# wiz16b8m4ct3_0_WIZ16B8M4CT3 register map
Vendor: Texas Instruments
Registers are 32-bit, read-write, reset 0x0 unless marked. A register's access mark holds for its fields unless they carry their own. Offsets are as the file gives them; [hi:lo] are bit positions.

## wiz16b8m4ct3_0_WIZ16B8M4CT3 (part 5 of 12)
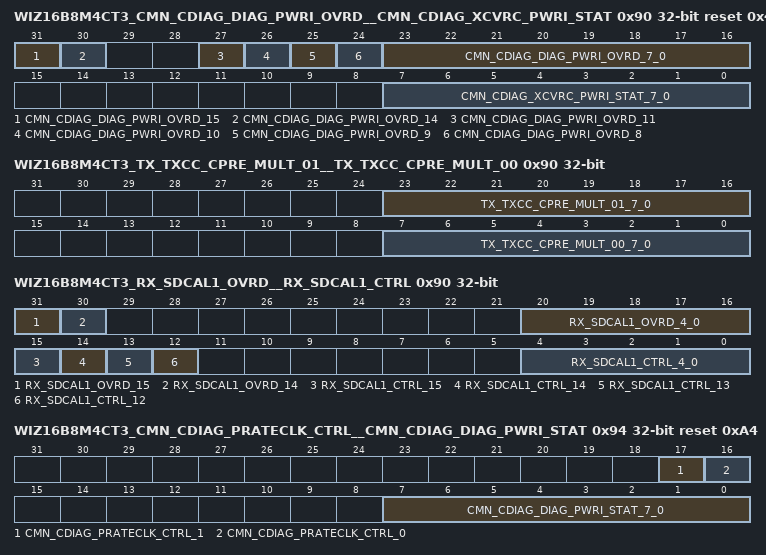
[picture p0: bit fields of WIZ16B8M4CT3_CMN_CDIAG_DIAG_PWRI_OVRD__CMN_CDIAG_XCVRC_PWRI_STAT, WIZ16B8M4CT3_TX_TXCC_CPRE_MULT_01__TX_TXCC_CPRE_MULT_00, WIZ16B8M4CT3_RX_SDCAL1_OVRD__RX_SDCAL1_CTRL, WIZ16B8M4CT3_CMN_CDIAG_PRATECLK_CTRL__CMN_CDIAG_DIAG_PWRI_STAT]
0x90 WIZ16B8M4CT3_CMN_CDIAG_DIAG_PWRI_OVRD__CMN_CDIAG_XCVRC_PWRI_STAT access per field reset 0x4240024
  [31] CMN_CDIAG_DIAG_PWRI_OVRD_15 rw — Power island controller input override enable: When enabled, the power island control state machine input override bits in this register will drive the power island control state machine directly, and override any control from other state machines in the macro. Note: The CDB power island must be triggered to be enabled, by accessing a register outside of the common control module control and diagnostic registers space, prior to enabling this function. Note: This bit must never change state in the same register write that any of the override bits it controls in this register are changed. 1'b0: Override disabled 1'b1: Override enabled
  [30] CMN_CDIAG_DIAG_PWRI_OVRD_14 rw — Power island controller output override enable: When enabled, the power island control state machine output override bits in this register will drive the power island control state machine outputs, and override any control from power island control state machine. Note: This bit must never change state in the same register write that any of the override bits it controls in this register are changed. 1'b0: Override disabled 1'b1: Override enabled
  [27] CMN_CDIAG_DIAG_PWRI_OVRD_11 rw — Power suspend request override: When enabled, this bit will override the power_suspend_req input of the power island control state machine.
  [26] CMN_CDIAG_DIAG_PWRI_OVRD_10 ro — Power suspend acknowledge: This is the current state of the power_suspend_ack output from the power island control state machine. Note: This bit will always be set to 1'b1 after the power island is enabled, as a function of the power island controller input override enable bit in this register.
  [25] CMN_CDIAG_DIAG_PWRI_OVRD_9 rw — Power recover request override: When enabled, this bit will override the power_recover_req input of the power island control state machine.
  [24] CMN_CDIAG_DIAG_PWRI_OVRD_8 ro — Power recover acknowledge: This is the current state of the power_recover_ack output from the power island control state machine. Note: This bit will always be set to 1'b1 after the power island is enabled, as a function of the power island controller input override enable bit in this register.
  [23:16] CMN_CDIAG_DIAG_PWRI_OVRD_7_0 rw — Power island controller output override: When enabled, the bits in this field will override the output signals from the power island control state machine. The following are the power island control state machine output signals, and the bits in this field that they are associated with. Bit 7: state_sandh Bit 6: state_ret_save Bit 5: state_ret_restore (active low) Bit 4: power_en_ph_1 Bit 3: power_en_ph_2 Bit 2: power_isolation Bit 1: power_por_reset_n Bit 0: power_rstr_reset_n The default value of the bits in this register are such that the power island is not forced to be switched on when the power island controller output override enable bit in this register is enabled. When using this register to switch this power island on and off, the bits in this field are required to change in a specific order with individual register writes. The writes must happen in the order specified below. 8'b00100100 : Power island is not being forced on 8'b10100100 8'b10110100 8'b10111100 8'b10111111 8'b10111011 8'b00111011 : Power island is being forced on 8'b10111011 8'b10111111 8'b11111111 8'b10111111 8'b10111110 8'b10100110 : Power island is being forced off, and in state retention 8'b10110110 8'b10111110 8'b10111111 8'b10011111 8'b10111111 8'b10111011 8'b00111011 : Power island is being forced on, with state restored
  [7:0] CMN_CDIAG_XCVRC_PWRI_STAT_7_0 ro — Power island controller output status: This field indicates the current state of the output signals from the power island control state machine. The following are the power island control state machine output signals, and the bits in this field that they are associated with. Bit 7: state_sandh Bit 6: state_ret_save Bit 5: state_ret_restore (active low) Bit 4: power_en_ph_1 Bit 3: power_en_ph_2 Bit 2: power_isolation Bit 1: power_por_reset_n Bit 0: power_rstr_reset_n
0x90 WIZ16B8M4CT3_TX_TXCC_CPRE_MULT_01__TX_TXCC_CPRE_MULT_00
  [23:16] TX_TXCC_CPRE_MULT_01_7_0 — Calculated pre emphasis multiplier value 01: The value in this field specifies the multiplier value used to generate the calculated pre emphasis value from the FS value when tx_deemphasis[1:0] = 2'b01. The following describes the multiplier value each bit in this field corresponds to. Bit 7 : 128/128 = 1.000000 Bit 6 : 64/128 = 0.500000 Bit 5 : 32/128 = 0.250000 Bit 4 : 16/128 = 0.125000 Bit 3 : 8/128 = 0.062500 Bit 2 : 4/128 = 0.031250 Bit 1 : 2/128 = 0.015625 Bit 0 : 1/128 = 0.0078125 Note: The output of the multiplier is 6 bits wide. It is possible to set the multiplier value here to a sufficiently large value to cause the multiplier result to be such that it can't be represented by a 6 bit value. In such a case, the multiplier output will be driven to 6'b111111.
  [7:0] TX_TXCC_CPRE_MULT_00_7_0 — Calculated pre emphasis multiplier value 00: The value in this field specifies the multiplier value used to generate the calculated pre emphasis value from the FS value when tx_deemphasis[1:0] = 2'b00. The following describes the multiplier value each bit in this field corresponds to. Bit 7 : 128/128 = 1.000000 Bit 6 : 64/128 = 0.500000 Bit 5 : 32/128 = 0.250000 Bit 4 : 16/128 = 0.125000 Bit 3 : 8/128 = 0.062500 Bit 2 : 4/128 = 0.031250 Bit 1 : 2/128 = 0.015625 Bit 0 : 1/128 = 0.0078125 Note: The output of the multiplier is 6 bits wide. It is possible to set the multiplier value here to a sufficiently large value to cause the multiplier result to be such that it can't be represented by a 6 bit value. In such a case, the multiplier output will be driven to 6'b111111.
0x90 WIZ16B8M4CT3_RX_SDCAL1_OVRD__RX_SDCAL1_CTRL access per field
  [31] RX_SDCAL1_OVRD_15 rw — Calibration code override enable: Activation (1'b1) of this register bit allows the calibration code determined during the automatic calibration process to be overridden. The override value is specified using the calibration code override value field of this register.
  [30] RX_SDCAL1_OVRD_14 rw — Analog calibration enable override: Activation (1'b1) of this register bit will force the analog calibration circuits to be enabled by activating the rxda_sd_cal_1_en enable and the rxda_sd_cal_1_clk clock.
  [20:16] RX_SDCAL1_OVRD_4_0 rw — Calibration code override value: These bits are used to override the calibration code determined during the automatic calibration process. The code written to these bits is valid when the calibration code override enable bit in this register is active. The codes in this field correspond to those described in the calibration code field in the Signal detect calibration 1 control register (!) on page 235.
  [15] RX_SDCAL1_CTRL_15 rw — Start calibration: Activating (1'b1) this bit will start the calibration process. This signal must remain active until the calibration process is complete. To start another calibration process, this register must first be set inactive (1'b0) until the bandbap calibration process done bit in this register is cleared. Note: This bit is intended to be for diagnostics purposes only. This calibration process is automatically activated internally by the power state machine. When using this bit, the user must wait until after the internally activated process completes.
  [14] RX_SDCAL1_CTRL_14 ro — Calibration process done: This bit will be set to 1'b1 when the calibration process is complete. It will be cleared by cmn_reset_n, or by the deactivation of the start calibration bit in this register after calibration is complete. Note: This bit is intended to be for diagnostics purposes only. Note: This bit is not likely to be observed as being set after internal automatic calibration is complete, because the internally generated run signal will be driven inactive immediately after the done signal is activated, and therefore the internal done signal will be cleared. Note: Three cmn_ref_clk cycles are required after the start of the calibration process to clear this signal.
  [13] RX_SDCAL1_CTRL_13 ro — No analog calibration response : This signal indicates that the calibration function has gone through the entire calibration process, reached the final calibration value, and the analog has not responded indicating that a valid calibration value has been reached. Note: Due to the nature of the calibration process, it is not possible to determine if the analog responded or not for the lowest code of 4'b1001. The reason for this is, when sequencing to lower codes, the calibration function is looking for the analog response to transition from 1'b1 to 1'b0. If the lowest calibration code is the correct code, the analog will respond with 1'b1, and the algorithm can't sequence to a lower code to look for the transition from 1'b1 to 1'b0. Similarly, if the analog is not responding, it is not possible to sequence to a lower code to detect this. Therefore, even when the calibration function selects this calibration code as valid, this bit will be set.
  [12] RX_SDCAL1_CTRL_12 ro — Current analog comparator response: This is the current state of the analog comparator response signal (rxda_sd_cal_0_comp). This signal is not synchronized, and is provided for diagnostic purposes only.
  [4:0] RX_SDCAL1_CTRL_4_0 ro — Calibration code: This is the calibration code that was determined by the calibration process. The following indicates how this encoding maps to the rxda_sd_cal_1_up and rxda_sd_cal_1_code signals going to the analog calibration function. The five bit value on the left is the value of this field. The one bit value on the right corresponds to the value of rxda_sd_cal_1_up. The four bit field corresponds to the value of rxda_sd_cal_1_code. 5'b01111 : 1'b1, 4'b1111 5'b01110 : 1'b1, 4'b1110 ... 5'b00010 : 1'b1, 4'b0010 5'b00001 : 1'b1, 4'b0001 5'b00000 : 1'b1, 4'b0000 5'b11111 : 1'b0, 4'b0001 5'b11110 : 1'b0, 4'b0010 ... 5'b10010 : 1'b0, 4'b1110 5'b10001 : 1'b0, 4'b1111
0x94 WIZ16B8M4CT3_CMN_CDIAG_PRATECLK_CTRL__CMN_CDIAG_DIAG_PWRI_STAT access per field reset 0xA4
  [17] CMN_CDIAG_PRATECLK_CTRL_1 rw — Common PLL 1 full rate and data rate source clock select: Selects the PLL source clock to use when generating the cmn_pll1_clk_fullrt, cmn_pll1_clk_datart0, and cmn_pll1_clk_datart1 clocks. 1'b0 : cmnda_pll1_clk_0 1'b1 : cmnda_pll1_clk_1
  [16] CMN_CDIAG_PRATECLK_CTRL_0 rw — Common PLL 0 full rate and data rate source clock select: Selects the PLL source clock to use when generating the cmn_pll0_clk_fullrt, cmn_pll0_clk_datart0, and cmn_pll0_clk_datart1 clocks. 1'b0 : cmnda_pll0_clk_0 1'b1 : cmnda_pll0_clk_1
  [7:0] CMN_CDIAG_DIAG_PWRI_STAT_7_0 ro — Power island controller output status: This field indicates the current state of the output signals from the power island control state machine. The following are the power island control state machine output signals, and the bits in this field that they are associated with. Bit 7: state_sandh Bit 6: state_ret_save Bit 5: state_ret_restore (active low) Bit 4: power_en_ph_1 Bit 3: power_en_ph_2 Bit 2: power_isolation Bit 1: power_por_reset_n Bit 0: power_rstr_reset_n
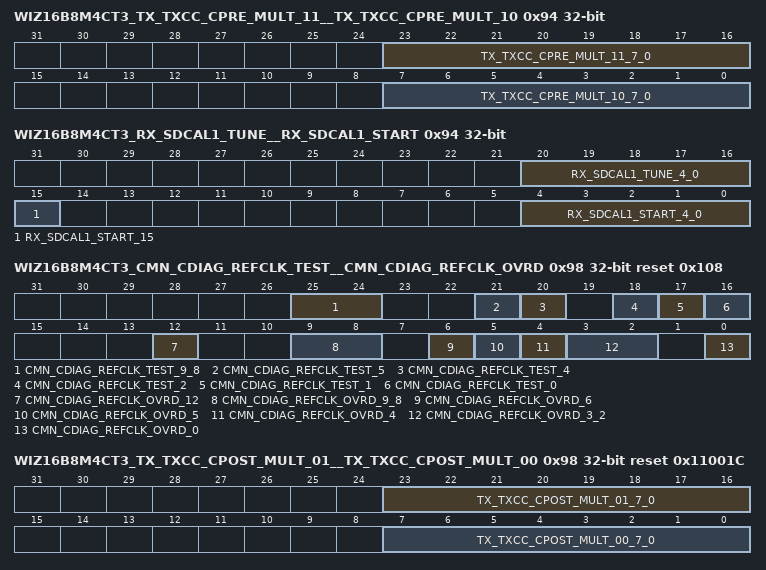
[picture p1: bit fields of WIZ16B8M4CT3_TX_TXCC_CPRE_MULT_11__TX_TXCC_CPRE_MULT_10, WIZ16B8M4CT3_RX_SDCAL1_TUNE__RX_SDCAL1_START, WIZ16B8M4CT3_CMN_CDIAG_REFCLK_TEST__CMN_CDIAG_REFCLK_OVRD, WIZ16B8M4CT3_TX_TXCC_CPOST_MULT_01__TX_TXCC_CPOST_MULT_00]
0x94 WIZ16B8M4CT3_TX_TXCC_CPRE_MULT_11__TX_TXCC_CPRE_MULT_10
  [23:16] TX_TXCC_CPRE_MULT_11_7_0 — Calculated pre emphasis multiplier value 11: The value in this field specifies the multiplier value used to generate the calculated pre emphasis value from the FS value when tx_deemphasis[1:0] = 2'b11. The following describes the multiplier value each bit in this field corresponds to. Bit 7 : 128/128 = 1.000000 Bit 6 : 64/128 = 0.500000 Bit 5 : 32/128 = 0.250000 Bit 4 : 16/128 = 0.125000 Bit 3 : 8/128 = 0.062500 Bit 2 : 4/128 = 0.031250 Bit 1 : 2/128 = 0.015625 Bit 0 : 1/128 = 0.0078125 Note: The output of the multiplier is 6 bits wide. It is possible to set the multiplier value here to a sufficiently large value to cause the multiplier result to be such that it can't be represented by a 6 bit value. In such a case, the multiplier output will be driven to 6'b111111.
  [7:0] TX_TXCC_CPRE_MULT_10_7_0 — Calculated pre emphasis multiplier value 10: The value in this field specifies the multiplier value used to generate the calculated pre emphasis value from the FS value when tx_deemphasis[1:0] = 2'b10. The following describes the multiplier value each bit in this field corresponds to. Bit 7 : 128/128 = 1.000000 Bit 6 : 64/128 = 0.500000 Bit 5 : 32/128 = 0.250000 Bit 4 : 16/128 = 0.125000 Bit 3 : 8/128 = 0.062500 Bit 2 : 4/128 = 0.031250 Bit 1 : 2/128 = 0.015625 Bit 0 : 1/128 = 0.0078125 Note: The output of the multiplier is 6 bits wide. It is possible to set the multiplier value here to a sufficiently large value to cause the multiplier result to be such that it can't be represented by a 6 bit value. In such a case, the multiplier output will be driven to 6'b111111.
0x94 WIZ16B8M4CT3_RX_SDCAL1_TUNE__RX_SDCAL1_START
  [20:16] RX_SDCAL1_TUNE_4_0 — Calibration tune value: The value of this field is added to the automatically calibrated code, or the override code if override is enabled. Note: This value is a twos complement value, so the calibrated code can be increased or decreased.
  [15] RX_SDCAL1_START_15 — Calibration direction: This controls the direction that the automatic calibration process steps the calibration codes in. 1'b0 : From 5'b10001 to 5'b01111. 1'b1 : From 5'b01111 to 5'b00000.
  [4:0] RX_SDCAL1_START_4_0 — Start calibration code: This is the calibration code that the calibration process starts with when automatic calibration is run. The codes in this field correspond to those described in the calibration code field in the Signal detect calibration 1 control register (!) on page 235.
0x98 WIZ16B8M4CT3_CMN_CDIAG_REFCLK_TEST__CMN_CDIAG_REFCLK_OVRD access per field reset 0x108
  [25:24] CMN_CDIAG_REFCLK_TEST_9_8 rw — Reserved - spare
  [21] CMN_CDIAG_REFCLK_TEST_5 rw — Reference clock driver 0 test mode enable: Enables the reference clock driver DC test mode, by controlling the cmnda_ref_clk0_drv_test_en signal going into the analog.
  [20] CMN_CDIAG_REFCLK_TEST_4 rw — Reference clock driver 0 test mode value: When enabled by the reference clock driver 0 test mode enable bit in this register, the value in this bit will be driven by the reference clock driver, by controlling the cmnda_ref_clk0_drv_test_val signal going into the analog.
  [18] CMN_CDIAG_REFCLK_TEST_2 rw — Reference clock receiver test mode enable: Enables the reference clock receiver DC test mode, by controlling the cmnda_ref_clk_rcv_test_en signal going into the analog.
  [17] CMN_CDIAG_REFCLK_TEST_1 ro — Reference clock receiver test mode PLL value: When enabled by the reference clock receiver test mode enable bit in this register, the value in this bit will be the value present on the PLL reference clock receiver. This bit is driven by thecmnda_ref_clk_rcv_test_pll_val signal driven from the analog.
  [16] CMN_CDIAG_REFCLK_TEST_0 ro — Reference clock receiver test mode digital value: When enabled by the reference clock receiver test mode enable bit in this register, the value in this bit will be the value present on the digital reference clock receiver. This bit is driven by thecmnda_ref_clk_rcv_test_dig_val signal driven from the analog.
  [12] CMN_CDIAG_REFCLK_OVRD_12 rw — Derived reference clock source select: Selects which PLL is the source for the derived reference clock, by driving the cmnda_ref_clk_der_src_sel signal to the analog. 1'b0: PLL 0 1'b1: PLL 1
  [9:8] CMN_CDIAG_REFCLK_OVRD_9_8 rw — Digital reference clock receiver hysteresis adjust: Control the amount of hysteresis used for the digital reference clock receiver, by driving the cmnda_ref_clk_dig_hyst_adj signal to the analog. 2'b00: -1X nominal 2'b01: Nominal 2'b10: +1X nominal 2'b11: +2X nominal
  [6] CMN_CDIAG_REFCLK_OVRD_6 rw — Analog reference clock enable override: This bit can be used to force the cmnda_ref_clk_en signal going to the analog to the active state. 1'b0 : No effect on the state of the cmnda_ref_clk_en signal. 1'b1 : The cmnda_ref_clk_en is forced to the active state.
  [5] CMN_CDIAG_REFCLK_OVRD_5 rw — Reference clock AC coupling cap bypass: Controls the bypassing of the AC coupling caps in the differential receiver. 1'b0: AC coupling caps not bypassed. 1'b1: AC coupling caps bypassed.
  [4] CMN_CDIAG_REFCLK_OVRD_4 rw — Derived reference clock enable: Enables the derived reference clock function, by driving the cmnda_ref_clk_der_en signal to the analog. Note: The option of using this clock is only intended to be for PCIe modes of operation. 1'b0: Derived clock function disabled. 1'b1: Derived clock function enabled.
  [3:2] CMN_CDIAG_REFCLK_OVRD_3_2 rw — Reference clock high pass filter control: Controls the cutoff frequency of the high pass filter in the reference clock receiver input. This controls this function by controlling the cmnda_ref_clk_filt_ctrl signal going into the analog. The following are the valid settings for this field and the corresponding cut off frequencies. 2'b00 : 20 - 49 MHz 2'b01 : 50 - 99 MHz 2'b10 : 100 - 149 MHz 2'b11 : 150 - 166 MHz
  [0] CMN_CDIAG_REFCLK_OVRD_0 rw — Reference clock receiver circuit clock control: 1'b0 : The analog reference clock receiver circuit for the digital drives the cmn_ref_clk_rcv pin. 1'b1 : The analog reference clock receiver circuit for the PLL drives the cmn_ref_clk_rcv pin.
0x98 WIZ16B8M4CT3_TX_TXCC_CPOST_MULT_01__TX_TXCC_CPOST_MULT_00 reset 0x11001C
  [23:16] TX_TXCC_CPOST_MULT_01_7_0 — Calculated post emphasis multiplier value 01: The value in this field specifies the multiplier value used to generate the calculated post emphasis value from the FS value when tx_deemphasis[1:0] = 2'b01. The following describes the multiplier value each bit in this field corresponds to. Bit 7 : 128/128 = 1.000000 Bit 6 : 64/128 = 0.500000 Bit 5 : 32/128 = 0.250000 Bit 4 : 16/128 = 0.125000 Bit 3 : 8/128 = 0.062500 Bit 2 : 4/128 = 0.031250 Bit 1 : 2/128 = 0.015625 Bit 0 : 1/128 = 0.0078125 Note: The output of the multiplier is 6 bits wide. It is possible to set the multiplier value here to a sufficiently large value to cause the multiplier result to be such that it can't be represented by a 6 bit value. In such a case, the multiplier output will be driven to 6'b111111.
  [7:0] TX_TXCC_CPOST_MULT_00_7_0 — Calculated post emphasis multiplier value 00: The value in this field specifies the multiplier value used to generate the calculated post emphasis value from the FS value when tx_deemphasis[1:0] = 2'b00. The following describes the multiplier value each bit in this field corresponds to. Bit 7 : 128/128 = 1.000000 Bit 6 : 64/128 = 0.500000 Bit 5 : 32/128 = 0.250000 Bit 4 : 16/128 = 0.125000 Bit 3 : 8/128 = 0.062500 Bit 2 : 4/128 = 0.031250 Bit 1 : 2/128 = 0.015625 Bit 0 : 1/128 = 0.0078125 Note: The output of the multiplier is 6 bits wide. It is possible to set the multiplier value here to a sufficiently large value to cause the multiplier result to be such that it can't be represented by a 6 bit value. In such a case, the multiplier output will be driven to 6'b111111.
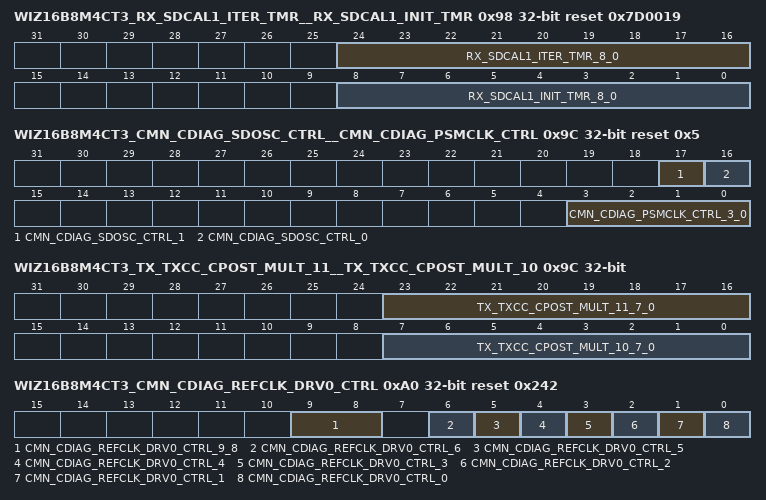
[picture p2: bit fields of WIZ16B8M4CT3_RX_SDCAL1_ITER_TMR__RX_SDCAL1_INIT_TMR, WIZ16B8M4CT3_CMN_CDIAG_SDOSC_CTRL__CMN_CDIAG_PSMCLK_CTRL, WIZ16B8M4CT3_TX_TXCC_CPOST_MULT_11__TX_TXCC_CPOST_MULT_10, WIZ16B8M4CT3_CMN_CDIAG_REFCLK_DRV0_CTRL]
0x98 WIZ16B8M4CT3_RX_SDCAL1_ITER_TMR__RX_SDCAL1_INIT_TMR reset 0x7D0019
  [24:16] RX_SDCAL1_ITER_TMR_8_0 — Iteration wait timer value: This is the number of cmn_ref_clk clocks to wait between when a value is placed on the calibration code signals going to the analog, and when the comparator value coming from the analog circuits can be checked. Note: This results in the minimum number of cmn_ref_clk clocks required to wait 5 uSec. Note: This should never be set to a value of less than 3.
  [8:0] RX_SDCAL1_INIT_TMR_8_0 — Initialization wait timer value: This is the number of cmn_ref_clk clocks to wait between when the analog calibration circuits are enabled, and when the first values are placed on the calibration code signals going to the analog. Note: This results in the minimum number of cmn_ref_clk clocks required to wait 1 uSec. Note: This should never be set to a value of less than 1.
0x9C WIZ16B8M4CT3_CMN_CDIAG_SDOSC_CTRL__CMN_CDIAG_PSMCLK_CTRL reset 0x5
  [17] CMN_CDIAG_SDOSC_CTRL_1 — Oscillator Enable Override Enable: This bit enables the oscillator enable override bit in this register to directly control the signal detect oscillator. 1'b0 : Override disabled. 1'b1 : Override enabled
  [16] CMN_CDIAG_SDOSC_CTRL_0 — Oscillator Enable Override: When enabled by the oscillator enable override enable bit in this register, this bit can be used to directly control the enable of the signal detect oscillator. 1'b0 : Disabled. 1'b1 : Enabled
  [3:0] CMN_CDIAG_PSMCLK_CTRL_3_0 — PSM clock divider value: The value of this field is used to control the divider setting of the PSM clock divider. The following are the encoded value for this field. 4'b0000 : Reserved 4'b0001 : Divide by 1 4'b0010 : Divide by 2 4'b0011 : Divide by 3 ... 4'b1111 : Divide by 15
0x9C WIZ16B8M4CT3_TX_TXCC_CPOST_MULT_11__TX_TXCC_CPOST_MULT_10
  [23:16] TX_TXCC_CPOST_MULT_11_7_0 — Calculated post emphasis multiplier value 11: The value in this field specifies the multiplier value used to generate the calculated post emphasis value from the FS value when tx_deemphasis[1:0] = 2'b11. The following describes the multiplier value each bit in this field corresponds to. Bit 7 : 128/128 = 1.000000 Bit 6 : 64/128 = 0.500000 Bit 5 : 32/128 = 0.250000 Bit 4 : 16/128 = 0.125000 Bit 3 : 8/128 = 0.062500 Bit 2 : 4/128 = 0.031250 Bit 1 : 2/128 = 0.015625 Bit 0 : 1/128 = 0.0078125 Note: The output of the multiplier is 6 bits wide. It is possible to set the multiplier value here to a sufficiently large value to cause the multiplier result to be such that it can't be represented by a 6 bit value. In such a case, the multiplier output will be driven to 6'b111111.
  [7:0] TX_TXCC_CPOST_MULT_10_7_0 — Calculated post emphasis multiplier value 10: The value in this field specifies the multiplier value used to generate the calculated post emphasis value from the FS value when tx_deemphasis[1:0] = 2'b10. The following describes the multiplier value each bit in this field corresponds to. Bit 7 : 128/128 = 1.000000 Bit 6 : 64/128 = 0.500000 Bit 5 : 32/128 = 0.250000 Bit 4 : 16/128 = 0.125000 Bit 3 : 8/128 = 0.062500 Bit 2 : 4/128 = 0.031250 Bit 1 : 2/128 = 0.015625 Bit 0 : 1/128 = 0.0078125 Note: The output of the multiplier is 6 bits wide. It is possible to set the multiplier value here to a sufficiently large value to cause the multiplier result to be such that it can't be represented by a 6 bit value. In such a case, the multiplier output will be driven to 6'b111111.
0xA0 WIZ16B8M4CT3_CMN_CDIAG_REFCLK_DRV0_CTRL reset 0x242
  [9:8] CMN_CDIAG_REFCLK_DRV0_CTRL_9_8 — Clock driver drive current tune: Controls the amplitude of the reference clock driver, by controlling the cmnda_ref_clk0_itune signal going to the analog. The following is the encoding of this field. 2'b00: 300mV pk-pk differential 2'b01: 350mV pk-pk differential 2'b10: 400mV pk-pk differential 2'b11: 450mV pk-pk differential
  [6] CMN_CDIAG_REFCLK_DRV0_CTRL_6 — Reference clock driver high Z: When the reference clock driver is disabled, this controls if the driver outputs are high Z or pulled low, by controlling the cmnda_ref_clk0_drv_highz signal going to the analog. 1'b0: Driver outputs pulled low 1'b1: Driver outputs high Z
  [5] CMN_CDIAG_REFCLK_DRV0_CTRL_5 — Clock driver termination: Enables the termination in the reference clock driver, by controlling the cmnda_ref_clk0_termination signal going to the analog. 1'b0: Disabled 1'b1: Enabled
  [4] CMN_CDIAG_REFCLK_DRV0_CTRL_4 — Clock select: Selects which reference clock that will be driven by the reference clock driver, by controlling the cmnda_ref_clk0_clk_select signal going to the analog. 1'b0: Received reference clock 1'b1: Derived reference clock
  [3] CMN_CDIAG_REFCLK_DRV0_CTRL_3 — Clock gate enable override enable: This bit enables the clock gate enable override bit in this register to override the clock gate of the reference clock driver.
  [2] CMN_CDIAG_REFCLK_DRV0_CTRL_2 — Clock gate enable override: When enabled by the clock gate enable override enable bit in this register, this bit can be used to directly control the clock gate enable of the reference clock driver by controlling the cmnda_ref_clk0_clk_gate_en signal going to the analog.
  [1] CMN_CDIAG_REFCLK_DRV0_CTRL_1 — Driver enable override enable: This bit enables the driver enable override bit in this register to override the enable of the reference clock driver. Note: This driver must not be enabled when a reference clock signal is being driven to the reference clock 0 bumps.
  [0] CMN_CDIAG_REFCLK_DRV0_CTRL_0 — Driver enable override: When enabled by the driver enable override enable bit in this register, this bit can be used to directly control the enable of the reference clock driver by controlling the cmnda_ref_clk0_drv_en signal going to the analog. Note: This driver must not be enabled when a reference clock signal is being driven to the reference clock 0 bumps.
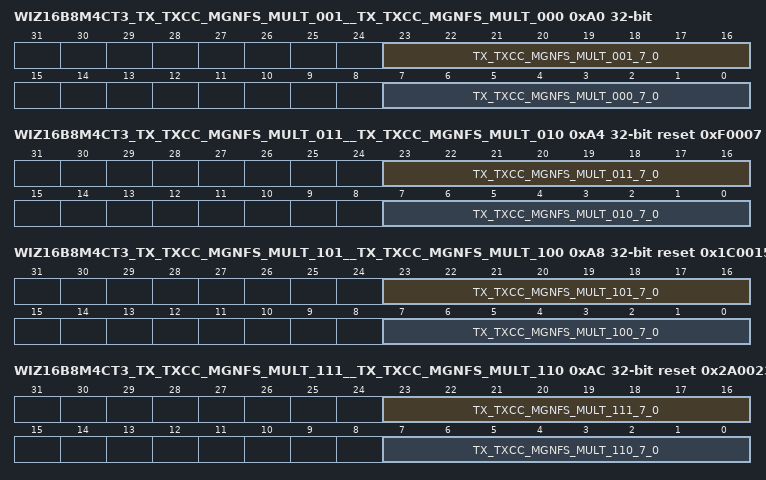
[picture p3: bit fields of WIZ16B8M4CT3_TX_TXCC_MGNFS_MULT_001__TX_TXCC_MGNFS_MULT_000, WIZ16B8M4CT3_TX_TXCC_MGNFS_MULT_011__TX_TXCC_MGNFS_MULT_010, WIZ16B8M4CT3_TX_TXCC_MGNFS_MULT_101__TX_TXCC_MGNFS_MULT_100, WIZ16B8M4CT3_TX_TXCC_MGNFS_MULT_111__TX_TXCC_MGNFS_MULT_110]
0xA0 WIZ16B8M4CT3_TX_TXCC_MGNFS_MULT_001__TX_TXCC_MGNFS_MULT_000
  [23:16] TX_TXCC_MGNFS_MULT_001_7_0 — Margin full swing multiplier value 001: The value in this field specifies the multiplier value used to generate the margin value from the resistor calibration value when tx_vmargin = 3'b001 and tx_low_power_swing_en = 1'b0. The following describes the multiplier value each bit in this field corresponds to. Bit 7 : 128/128 = 1.000000 Bit 6 : 64/128 = 0.500000 Bit 5 : 32/128 = 0.250000 Bit 4 : 16/128 = 0.125000 Bit 3 : 8/128 = 0.062500 Bit 2 : 4/128 = 0.031250 Bit 1 : 2/128 = 0.015625 Bit 0 : 1/128 = 0.0078125 Note: The largest value this is allowed to be set to is 54/128. Note: The output of the multiplier is 6 bits wide. It is possible to set the multiplier value here to a sufficiently large value to cause the multiplier result to be such that it can't be represented by a 6 bit value. In such a case, the multiplier output will be driven to 6'b111111.
  [7:0] TX_TXCC_MGNFS_MULT_000_7_0 — Margin full swing multiplier value 000: The value in this field specifies the multiplier value used to generate the margin value from the resistor calibration value when tx_vmargin = 3'b000 and tx_low_power_swing_en = 1'b0. The following describes the multiplier value each bit in this field corresponds to. Bit 7 : 128/128 = 1.000000 Bit 6 : 64/128 = 0.500000 Bit 5 : 32/128 = 0.250000 Bit 4 : 16/128 = 0.125000 Bit 3 : 8/128 = 0.062500 Bit 2 : 4/128 = 0.031250 Bit 1 : 2/128 = 0.015625 Bit 0 : 1/128 = 0.0078125 Note: The largest value this is allowed to be set to is 54/128. Note: The output of the multiplier is 6 bits wide. It is possible to set the multiplier value here to a sufficiently large value to cause the multiplier result to be such that it can't be represented by a 6 bit value. In such a case, the multiplier output will be driven to 6'b111111.
0xA4 WIZ16B8M4CT3_TX_TXCC_MGNFS_MULT_011__TX_TXCC_MGNFS_MULT_010 reset 0xF0007
  [23:16] TX_TXCC_MGNFS_MULT_011_7_0 — Margin full swing multiplier value 011: The value in this field specifies the multiplier value used to generate the margin value from the resistor calibration value when tx_vmargin = 3'b011 and tx_low_power_swing_en = 1'b0. The following describes the multiplier value each bit in this field corresponds to. Bit 7 : 128/128 = 1.000000 Bit 6 : 64/128 = 0.500000 Bit 5 : 32/128 = 0.250000 Bit 4 : 16/128 = 0.125000 Bit 3 : 8/128 = 0.062500 Bit 2 : 4/128 = 0.031250 Bit 1 : 2/128 = 0.015625 Bit 0 : 1/128 = 0.0078125 Note: The largest value this is allowed to be set to is 54/128. Note: The output of the multiplier is 6 bits wide. It is possible to set the multiplier value here to a sufficiently large value to cause the multiplier result to be such that it can't be represented by a 6 bit value. In such a case, the multiplier output will be driven to 6'b111111.
  [7:0] TX_TXCC_MGNFS_MULT_010_7_0 — Margin full swing multiplier value 010: The value in this field specifies the multiplier value used to generate the margin value from the resistor calibration value when tx_vmargin = 3'b010 and tx_low_power_swing_en = 1'b0. The following describes the multiplier value each bit in this field corresponds to. Bit 7 : 128/128 = 1.000000 Bit 6 : 64/128 = 0.500000 Bit 5 : 32/128 = 0.250000 Bit 4 : 16/128 = 0.125000 Bit 3 : 8/128 = 0.062500 Bit 2 : 4/128 = 0.031250 Bit 1 : 2/128 = 0.015625 Bit 0 : 1/128 = 0.0078125 Note: The largest value this is allowed to be set to is 54/128. Note: The output of the multiplier is 6 bits wide. It is possible to set the multiplier value here to a sufficiently large value to cause the multiplier result to be such that it can't be represented by a 6 bit value. In such a case, the multiplier output will be driven to 6'b111111.
0xA8 WIZ16B8M4CT3_TX_TXCC_MGNFS_MULT_101__TX_TXCC_MGNFS_MULT_100 reset 0x1C0015
  [23:16] TX_TXCC_MGNFS_MULT_101_7_0 — Margin full swing multiplier value 101: The value in this field specifies the multiplier value used to generate the margin value from the resistor calibration value when tx_vmargin = 3'b101 and tx_low_power_swing_en = 1'b0. The following describes the multiplier value each bit in this field corresponds to. Bit 7 : 128/128 = 1.000000 Bit 6 : 64/128 = 0.500000 Bit 5 : 32/128 = 0.250000 Bit 4 : 16/128 = 0.125000 Bit 3 : 8/128 = 0.062500 Bit 2 : 4/128 = 0.031250 Bit 1 : 2/128 = 0.015625 Bit 0 : 1/128 = 0.0078125 Note: The largest value this is allowed to be set to is 54/128. Note: The output of the multiplier is 6 bits wide. It is possible to set the multiplier value here to a sufficiently large value to cause the multiplier result to be such that it can't be represented by a 6 bit value. In such a case, the multiplier output will be driven to 6'b111111.
  [7:0] TX_TXCC_MGNFS_MULT_100_7_0 — Margin full swing multiplier value 100: The value in this field specifies the multiplier value used to generate the margin value from the resistor calibration value when tx_vmargin = 3'b100 and tx_low_power_swing_en = 1'b0. The following describes the multiplier value each bit in this field corresponds to. Bit 7 : 128/128 = 1.000000 Bit 6 : 64/128 = 0.500000 Bit 5 : 32/128 = 0.250000 Bit 4 : 16/128 = 0.125000 Bit 3 : 8/128 = 0.062500 Bit 2 : 4/128 = 0.031250 Bit 1 : 2/128 = 0.015625 Bit 0 : 1/128 = 0.0078125 Note: The largest value this is allowed to be set to is 54/128. Note: The output of the multiplier is 6 bits wide. It is possible to set the multiplier value here to a sufficiently large value to cause the multiplier result to be such that it can't be represented by a 6 bit value. In such a case, the multiplier output will be driven to 6'b111111.
0xAC WIZ16B8M4CT3_TX_TXCC_MGNFS_MULT_111__TX_TXCC_MGNFS_MULT_110 reset 0x2A0023
  [23:16] TX_TXCC_MGNFS_MULT_111_7_0 — Margin full swing multiplier value 111: The value in this field specifies the multiplier value used to generate the margin value from the resistor calibration value when tx_vmargin = 3'b111 and tx_low_power_swing_en = 1'b0. The following describes the multiplier value each bit in this field corresponds to. Bit 7 : 128/128 = 1.000000 Bit 6 : 64/128 = 0.500000 Bit 5 : 32/128 = 0.250000 Bit 4 : 16/128 = 0.125000 Bit 3 : 8/128 = 0.062500 Bit 2 : 4/128 = 0.031250 Bit 1 : 2/128 = 0.015625 Bit 0 : 1/128 = 0.0078125 Note: The largest value this is allowed to be set to is 54/128. Note: The output of the multiplier is 6 bits wide. It is possible to set the multiplier value here to a sufficiently large value to cause the multiplier result to be such that it can't be represented by a 6 bit value. In such a case, the multiplier output will be driven to 6'b111111.
  [7:0] TX_TXCC_MGNFS_MULT_110_7_0 — Margin full swing multiplier value 110: The value in this field specifies the multiplier value used to generate the margin value from the resistor calibration value when tx_vmargin = 3'b110 and tx_low_power_swing_en = 1'b0. The following describes the multiplier value each bit in this field corresponds to. Bit 7 : 128/128 = 1.000000 Bit 6 : 64/128 = 0.500000 Bit 5 : 32/128 = 0.250000 Bit 4 : 16/128 = 0.125000 Bit 3 : 8/128 = 0.062500 Bit 2 : 4/128 = 0.031250 Bit 1 : 2/128 = 0.015625 Bit 0 : 1/128 = 0.0078125 Note: The largest value this is allowed to be set to is 54/128. Note: The output of the multiplier is 6 bits wide. It is possible to set the multiplier value here to a sufficiently large value to cause the multiplier result to be such that it can't be represented by a 6 bit value. In such a case, the multiplier output will be driven to 6'b111111.
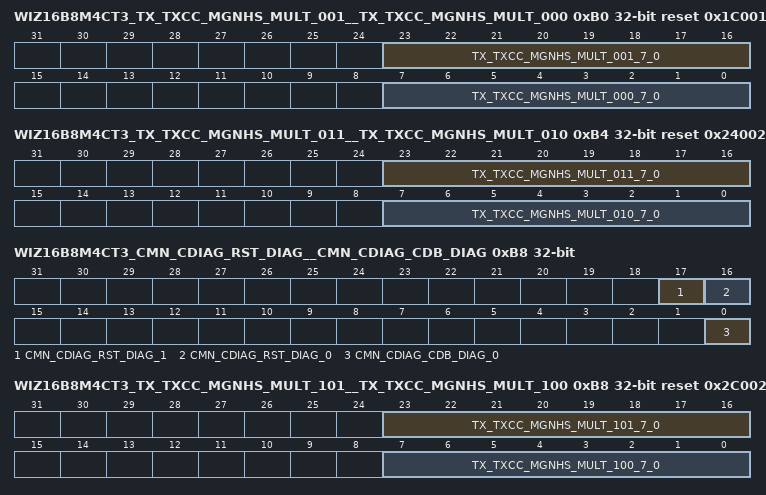
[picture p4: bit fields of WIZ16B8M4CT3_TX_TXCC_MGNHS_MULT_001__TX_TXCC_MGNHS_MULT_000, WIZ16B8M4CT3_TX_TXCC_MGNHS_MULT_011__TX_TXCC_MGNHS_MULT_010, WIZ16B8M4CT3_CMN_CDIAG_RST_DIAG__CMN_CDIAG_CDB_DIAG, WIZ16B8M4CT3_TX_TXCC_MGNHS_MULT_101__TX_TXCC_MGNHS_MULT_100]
0xB0 WIZ16B8M4CT3_TX_TXCC_MGNHS_MULT_001__TX_TXCC_MGNHS_MULT_000 reset 0x1C001C
  [23:16] TX_TXCC_MGNHS_MULT_001_7_0 — Margin half swing multiplier value 001: The value in this field specifies the multiplier value used to generate the margin value from the resistor calibration value when tx_vmargin = 3'b001 and tx_low_power_swing_en = 1'b1. The following describes the multiplier value each bit in this field corresponds to. Bit 7 : 128/128 = 1.000000 Bit 6 : 64/128 = 0.500000 Bit 5 : 32/128 = 0.250000 Bit 4 : 16/128 = 0.125000 Bit 3 : 8/128 = 0.062500 Bit 2 : 4/128 = 0.031250 Bit 1 : 2/128 = 0.015625 Bit 0 : 1/128 = 0.0078125 Note: The largest value this is allowed to be set to is 54/128. Note: The output of the multiplier is 6 bits wide. It is possible to set the multiplier value here to a sufficiently large value to cause the multiplier result to be such that it can't be represented by a 6 bit value. In such a case, the multiplier output will be driven to 6'b111111.
  [7:0] TX_TXCC_MGNHS_MULT_000_7_0 — Margin half swing multiplier value 000: The value in this field specifies the multiplier value used to generate the margin value from the resistor calibration value when tx_vmargin = 3'b000 and tx_low_power_swing_en = 1'b1. The following describes the multiplier value each bit in this field corresponds to. Bit 7 : 128/128 = 1.000000 Bit 6 : 64/128 = 0.500000 Bit 5 : 32/128 = 0.250000 Bit 4 : 16/128 = 0.125000 Bit 3 : 8/128 = 0.062500 Bit 2 : 4/128 = 0.031250 Bit 1 : 2/128 = 0.015625 Bit 0 : 1/128 = 0.0078125 Note: The largest value this is allowed to be set to is 54/128. Note: The output of the multiplier is 6 bits wide. It is possible to set the multiplier value here to a sufficiently large value to cause the multiplier result to be such that it can't be represented by a 6 bit value. In such a case, the multiplier output will be driven to 6'b111111.
0xB0 WIZ16B8M4CT3_RX_SAMP_DAC_CTRL reset 0x14
  [5:0] RX_SAMP_DAC_CTRL_5_0 — Sampler error DAC value: Specifies the input value to the sampler error DAC. This value is a twos complement binary number, with the range specified below. 6'b011111: Maximum. 6'b000000: Center point of the data eye. 6'b100001: Minimum. Note : Even though this register can be set to as low as 6'b100001, it should never be set below the value of 6'b000000 when the VGA gain target adjustment algorithm is enabled in the REE. Doing so can result in an underflow condition.
0xB4 WIZ16B8M4CT3_TX_TXCC_MGNHS_MULT_011__TX_TXCC_MGNHS_MULT_010 reset 0x240020
  [23:16] TX_TXCC_MGNHS_MULT_011_7_0 — Margin half swing multiplier value 011: The value in this field specifies the multiplier value used to generate the margin value from the resistor calibration value when tx_vmargin = 3'b011 and tx_low_power_swing_en = 1'b1. The following describes the multiplier value each bit in this field corresponds to. Bit 7 : 128/128 = 1.000000 Bit 6 : 64/128 = 0.500000 Bit 5 : 32/128 = 0.250000 Bit 4 : 16/128 = 0.125000 Bit 3 : 8/128 = 0.062500 Bit 2 : 4/128 = 0.031250 Bit 1 : 2/128 = 0.015625 Bit 0 : 1/128 = 0.0078125 Note: The largest value this is allowed to be set to is 54/128. Note: The output of the multiplier is 6 bits wide. It is possible to set the multiplier value here to a sufficiently large value to cause the multiplier result to be such that it can't be represented by a 6 bit value. In such a case, the multiplier output will be driven to 6'b111111.
  [7:0] TX_TXCC_MGNHS_MULT_010_7_0 — Margin half swing multiplier value 010: The value in this field specifies the multiplier value used to generate the margin value from the resistor calibration value when tx_vmargin = 3'b010 and tx_low_power_swing_en = 1'b1. The following describes the multiplier value each bit in this field corresponds to. Bit 7 : 128/128 = 1.000000 Bit 6 : 64/128 = 0.500000 Bit 5 : 32/128 = 0.250000 Bit 4 : 16/128 = 0.125000 Bit 3 : 8/128 = 0.062500 Bit 2 : 4/128 = 0.031250 Bit 1 : 2/128 = 0.015625 Bit 0 : 1/128 = 0.0078125 Note: The largest value this is allowed to be set to is 54/128. Note: The output of the multiplier is 6 bits wide. It is possible to set the multiplier value here to a sufficiently large value to cause the multiplier result to be such that it can't be represented by a 6 bit value. In such a case, the multiplier output will be driven to 6'b111111.
0xB8 WIZ16B8M4CT3_CMN_CDIAG_RST_DIAG__CMN_CDIAG_CDB_DIAG ro
  [17] CMN_CDIAG_RST_DIAG_1 — Current state of the cdb_isl_ctrl_sm_reset_n reset.
  [16] CMN_CDIAG_RST_DIAG_0 — Current state of the cmn_reset_sync_n reset.
  [0] CMN_CDIAG_CDB_DIAG_0 — CDB bus error: This bit will be set when the internal CDB watchdog timer expires. It is automatically cleared on a read of this register.
0xB8 WIZ16B8M4CT3_TX_TXCC_MGNHS_MULT_101__TX_TXCC_MGNHS_MULT_100 reset 0x2C0028
  [23:16] TX_TXCC_MGNHS_MULT_101_7_0 — Margin half swing multiplier value 101: The value in this field specifies the multiplier value used to generate the margin value from the resistor calibration value when tx_vmargin = 3'b101 and tx_low_power_swing_en = 1'b1. The following describes the multiplier value each bit in this field corresponds to. Bit 7 : 128/128 = 1.000000 Bit 6 : 64/128 = 0.500000 Bit 5 : 32/128 = 0.250000 Bit 4 : 16/128 = 0.125000 Bit 3 : 8/128 = 0.062500 Bit 2 : 4/128 = 0.031250 Bit 1 : 2/128 = 0.015625 Bit 0 : 1/128 = 0.0078125 Note: The largest value this is allowed to be set to is 54/128. Note: The output of the multiplier is 6 bits wide. It is possible to set the multiplier value here to a sufficiently large value to cause the multiplier result to be such that it can't be represented by a 6 bit value. In such a case, the multiplier output will be driven to 6'b111111.
  [7:0] TX_TXCC_MGNHS_MULT_100_7_0 — Margin half swing multiplier value 100: The value in this field specifies the multiplier value used to generate the margin value from the resistor calibration value when tx_vmargin = 3'b100 and tx_low_power_swing_en = 1'b1. The following describes the multiplier value each bit in this field corresponds to. Bit 7 : 128/128 = 1.000000 Bit 6 : 64/128 = 0.500000 Bit 5 : 32/128 = 0.250000 Bit 4 : 16/128 = 0.125000 Bit 3 : 8/128 = 0.062500 Bit 2 : 4/128 = 0.031250 Bit 1 : 2/128 = 0.015625 Bit 0 : 1/128 = 0.0078125 Note: The largest value this is allowed to be set to is 54/128. Note: The output of the multiplier is 6 bits wide. It is possible to set the multiplier value here to a sufficiently large value to cause the multiplier result to be such that it can't be represented by a 6 bit value. In such a case, the multiplier output will be driven to 6'b111111.
0xBC WIZ16B8M4CT3_CMN_CDIAG_DCYA
  [23:16] CMN_CDIAG_DCYA_7_0 — Reserved - spare
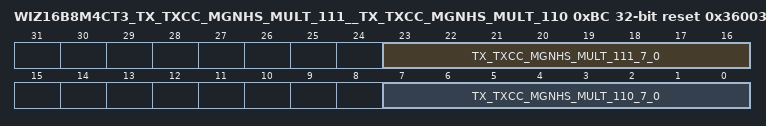
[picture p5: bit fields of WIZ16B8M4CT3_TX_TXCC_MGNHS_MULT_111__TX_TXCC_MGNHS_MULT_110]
0xBC WIZ16B8M4CT3_TX_TXCC_MGNHS_MULT_111__TX_TXCC_MGNHS_MULT_110 reset 0x360033
  [23:16] TX_TXCC_MGNHS_MULT_111_7_0 — Margin half swing multiplier value 111: The value in this field specifies the multiplier value used to generate the margin value from the resistor calibration value when tx_vmargin = 3'b111 and tx_low_power_swing_en = 1'b1. The following describes the multiplier value each bit in this field corresponds to. Bit 7 : 128/128 = 1.000000 Bit 6 : 64/128 = 0.500000 Bit 5 : 32/128 = 0.250000 Bit 4 : 16/128 = 0.125000 Bit 3 : 8/128 = 0.062500 Bit 2 : 4/128 = 0.031250 Bit 1 : 2/128 = 0.015625 Bit 0 : 1/128 = 0.0078125 Note: The largest value this is allowed to be set to is 54/128. Note: The output of the multiplier is 6 bits wide. It is possible to set the multiplier value here to a sufficiently large value to cause the multiplier result to be such that it can't be represented by a 6 bit value. In such a case, the multiplier output will be driven to 6'b111111.
  [7:0] TX_TXCC_MGNHS_MULT_110_7_0 — Margin half swing multiplier value 110: The value in this field specifies the multiplier value used to generate the margin value from the resistor calibration value when tx_vmargin = 3'b110 and tx_low_power_swing_en = 1'b1. The following describes the multiplier value each bit in this field corresponds to. Bit 7 : 128/128 = 1.000000 Bit 6 : 64/128 = 0.500000 Bit 5 : 32/128 = 0.250000 Bit 4 : 16/128 = 0.125000 Bit 3 : 8/128 = 0.062500 Bit 2 : 4/128 = 0.031250 Bit 1 : 2/128 = 0.015625 Bit 0 : 1/128 = 0.0078125 Note: The largest value this is allowed to be set to is 54/128. Note: The output of the multiplier is 6 bits wide. It is possible to set the multiplier value here to a sufficiently large value to cause the multiplier result to be such that it can't be represented by a 6 bit value. In such a case, the multiplier output will be driven to 6'b111111.
